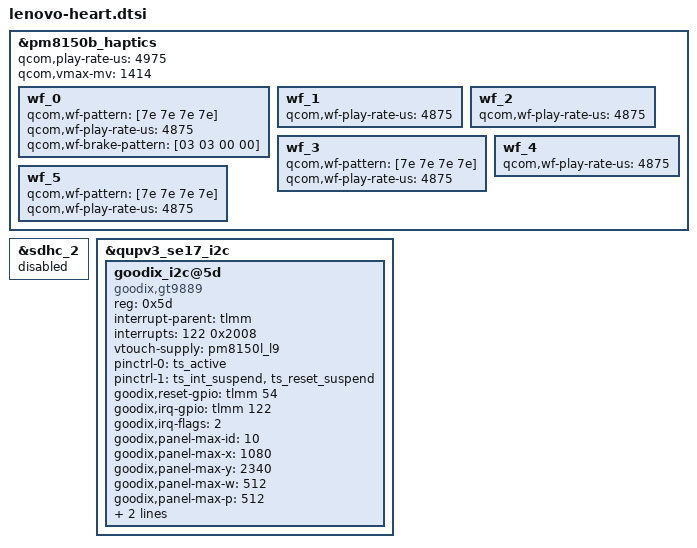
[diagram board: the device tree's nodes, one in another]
/* Copyright (c) 2016-2017, The Linux Foundation. All rights reserved.
 *
 * This program is free software; you can redistribute it and/or modify
 * it under the terms of the GNU General Public License version 2 and
 * only version 2 as published by the Free Software Foundation.
 *
 * This program is distributed in the hope that it will be useful,
 * but WITHOUT ANY WARRANTY; without even the implied warranty of
 * MERCHANTABILITY or FITNESS FOR A PARTICULAR PURPOSE.  See the
 * GNU General Public License for more details.
 */

#include "lenovo-heart-goodixfp.dtsi"

&pm8150b_haptics {
	qcom,play-rate-us = <4975>;
	qcom,vmax-mv = <1414>;

	wf_0 {
		/* CLICK */
		/delete-property/qcom,lra-auto-resonance-disable;
		qcom,wf-pattern = [7e 7e 7e 7e];
		qcom,wf-play-rate-us = <4875>;
		qcom,wf-brake-pattern = [03 03 00 00];
	};
	wf_1 {
		/* DOUBLE CLICK */
		/delete-property/qcom,lra-auto-resonance-disable;
		qcom,wf-play-rate-us = <4875>;
	};
	wf_2 {
		/* TICK */
		/delete-property/qcom,lra-auto-resonance-disable;
		qcom,wf-play-rate-us = <4875>;
	};
	wf_3 {
		/* THUD */
		/delete-property/qcom,lra-auto-resonance-disable;
		qcom,wf-pattern = [7e 7e 7e 7e];
		qcom,wf-play-rate-us = <4875>;
	};
	wf_4 {
		/* POP */
		/delete-property/qcom,lra-auto-resonance-disable;
		qcom,wf-play-rate-us = <4875>;
	};
	wf_5 {
		/* HEAVY CLICK */
		/delete-property/qcom,lra-auto-resonance-disable;
		qcom,wf-pattern = [7e 7e 7e 7e];
		qcom,wf-play-rate-us = <4875>;
	};
};

&sdhc_2 {
	status = "disabled";
};

&qupv3_se17_i2c {
	status = "ok";

	goodix_i2c@5d {
		compatible = "goodix,gt9889";
		reg = <0x5d>;
		status = "ok";
		interrupt-parent = <&tlmm>;
		interrupts = <122 0x2008>;
		vtouch-supply = <&pm8150l_l9>;
		pinctrl-names = "pmx_ts_active","pmx_ts_suspend";
		pinctrl-0 = <&ts_active>;
		pinctrl-1 = <&ts_int_suspend &ts_reset_suspend>;
		goodix,reset-gpio = <&tlmm 54 0x0>;
		goodix,irq-gpio = <&tlmm 122 0x2008>;
		goodix,irq-flags = <2>; /* 1:trigger rising, 2:trigger falling;*/
		goodix,panel-max-id = <10>;
		goodix,panel-max-x = <1080>;
		goodix,panel-max-y = <2340>;
		goodix,panel-max-w = <512>;
		goodix,panel-max-p = <512>;
		/* goodix,panel-key-map = <158 172 217>;*/ /*KEY_BACK, KEY_HOMEPAGE, KEY_SEARCH*/
		goodix,power-on-delay-us = <300000>; /*300ms*/
		goodix,power-off-delay-us = <5000>;
		/*goodix,swap-axis;*/
		/* goodix,x2x; */
		/* goodix,y2y; */
	};
};
